# FM33FH0XX register map
File version: 1.0
CPU: SC000 r1p0, little endian, no MPU, no FPU, 3 interrupt priority bits
Registers are 32-bit, read-write, reset 0x0 unless marked. A register's access mark holds for its fields unless they carry their own. Offsets are from the block's base; [hi:lo] are bit positions; {n}, {i} and the like mark numbered series; 'fields as' and 'values as' point back to an identical list.

## DMA — DMA module information
Base 0x40000400
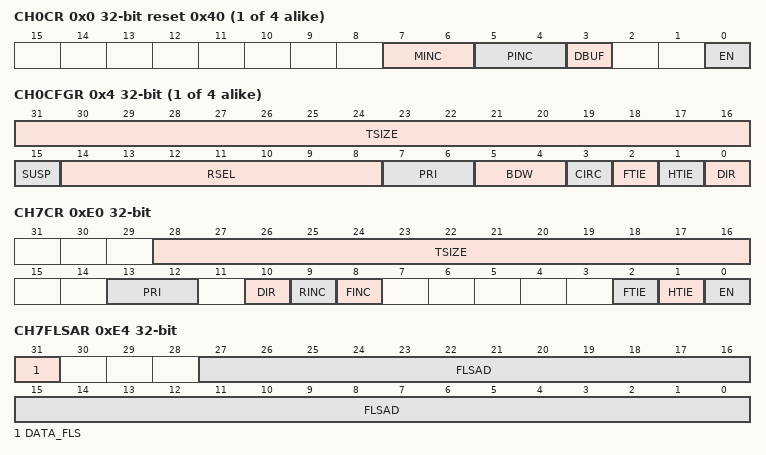
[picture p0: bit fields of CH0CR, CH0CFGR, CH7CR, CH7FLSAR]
{0x0+0x20*i} CH{i}CR reset 0x40 (i=0..3)
  [7:6] MINC — MINC field description
  [5:4] PINC — PINC field description
  [3] DBUF — DBUF field description
  [0] EN — EN field description
{0x4+0x20*i} CH{i}CFGR (i=0..3)
  [31:16] TSIZE — TSIZE field description
  [15] SUSP — SUSP field description
  [14:8] RSEL — RSEL field description
  [7:6] PRI — PRI field description
  [5:4] BDW — BDW field description
  [3] CIRC — CIRC field description
  [2] FTIE — FTIE field description
  [1] HTIE — HTIE field description
  [0] DIR — DIR field description
{0x8+0x20*i} CH{i}PAR (i=0..3)
  [31:0] PAD — PAD field description
{0xC+0x20*i} CH{i}MAR0 (i=0..3)
  [31:0] MAD0 — MAD0 field description
{0x10+0x20*i} CH{i}MAR1 (i=0..3)
  [31:0] MAD1 — MAD1 field description
0xE0 CH7CR
  [28:16] TSIZE — TSIZE field description
  [13:12] PRI — PRI field description
  [10] DIR — DIR field description
  [9] RINC — RINC field description
  [8] FINC — FINC field description
  [2] FTIE — FTIE field description
  [1] HTIE — HTIE field description
  [0] EN — EN field description
0xE4 CH7FLSAR
  [31] DATA_FLS — DATA_FLS field description
  [27:0] FLSAD — FLSAD field description
0xE8 CH7RAMAR
  [23:0] RAMAD — RAMAD field description
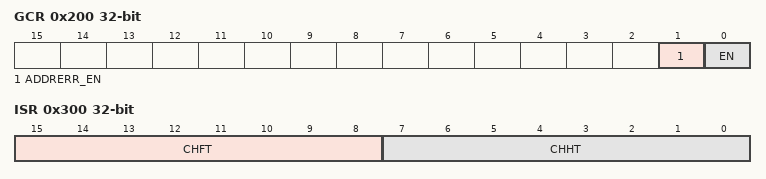
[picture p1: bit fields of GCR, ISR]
0x200 GCR
  [1] ADDRERR_EN — ADDRERR_EN field description
  [0] EN — EN field description
0x204 SWRR
  [6:0] SWTRIG — SWTRIG field description
0x300 ISR
  [15:8] CHFT — CHFT field description
  [7:0] CHHT — CHHT field description
{0x304+4i} CH{i}TFSADDR (i=0..3)
  [15:0] CNT ro — CNT field description

## FLS — FLS module information
Base 0x40001000
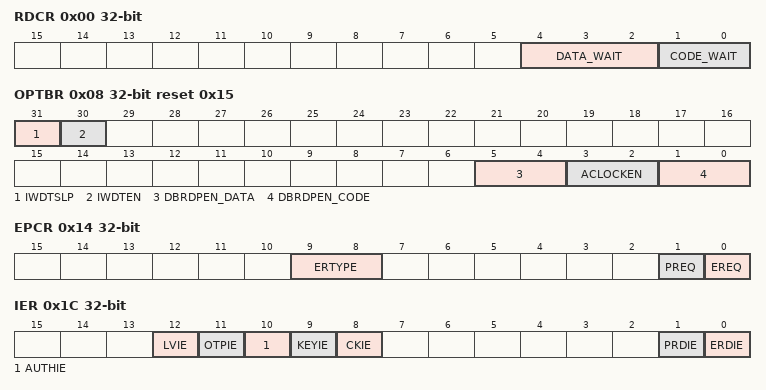
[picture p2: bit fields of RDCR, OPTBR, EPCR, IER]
0x00 RDCR
  [4:2] DATA_WAIT — DATA_WAIT field description
  [1:0] CODE_WAIT — CODE_WAIT field description
0x04 PFCR
  [0] EN — EN field description
0x08 OPTBR reset 0x15
  [31] IWDTSLP ro — IWDTSLP field description
  [30] IWDTEN ro — IWDTEN field description
  [5:4] DBRDPEN_DATA ro — DBRDPEN_DATA field description
  [3:2] ACLOCKEN ro — ACLOCKEN field description
  [1:0] DBRDPEN_CODE ro — DBRDPEN_CODE field description
0x14 EPCR
  [9:8] ERTYPE — ERTYPE field description
  [1] PREQ — PREQ field description
  [0] EREQ — EREQ field description
0x18 KEY
  [31:0] KEY wo — KEY field description
0x1C IER
  [12] LVIE — LVIE field description
  [11] OTPIE — OTPIE field description
  [10] AUTHIE — AUTHIE field description
  [9] KEYIE — KEYIE field description
  [8] CKIE — CKIE field description
  [1] PRDIE — PRDIE field description
  [0] ERDIE — ERDIE field description
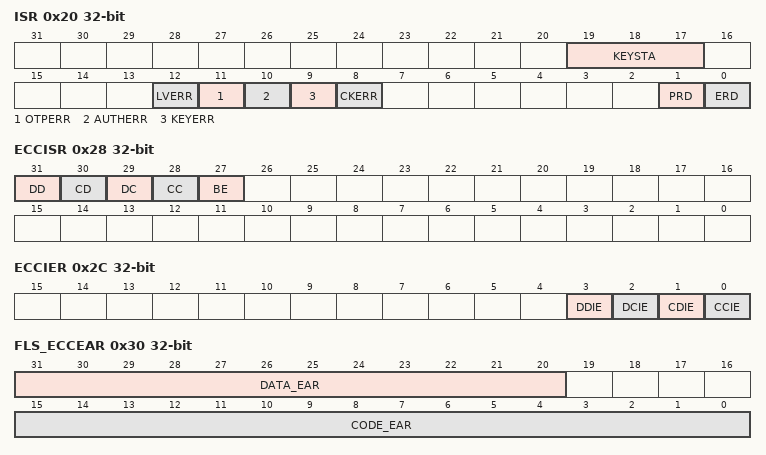
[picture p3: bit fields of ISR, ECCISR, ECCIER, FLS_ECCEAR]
0x20 ISR
  [19:17] KEYSTA ro — KEYSTA field description
  [12] LVERR — LVERR field description
  [11] OTPERR — OTPERR field description
  [10] AUTHERR — AUTHERR field description
  [9] KEYERR — KEYERR field description
  [8] CKERR — CKERR field description
  [1] PRD — PRD field description
  [0] ERD — ERD field description
0x28 ECCISR
  [31] DD — DD field description
  [30] CD — CD field description
  [29] DC — DC field description
  [28] CC — CC field description
  [27] BE — BE field description
0x2C ECCIER
  [3] DDIE — DDIE field description
  [2] DCIE — DCIE field description
  [1] CDIE — CDIE field description
  [0] CCIE — CCIE field description
0x30 FLS_ECCEAR
  [31:20] DATA_EAR ro — DATA_EAR field description
  [15:0] CODE_EAR ro — CODE_EAR field description
{0x5C+4i} ACLOCK{i} reset 0xFFFFFFFF (i=1..3)
  [31:0] LOCK{i} — LOCK{i} field description
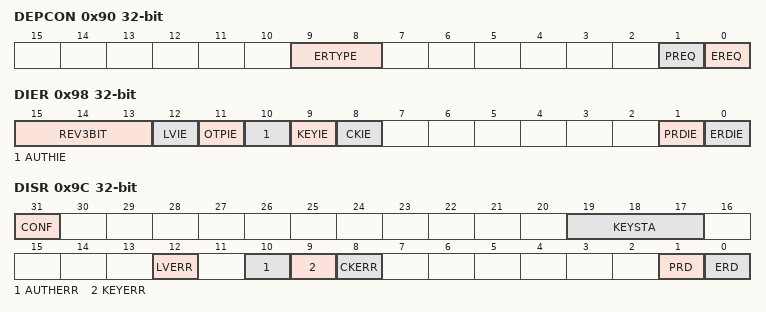
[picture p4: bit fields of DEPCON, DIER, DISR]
0x90 DEPCON
  fields as EPCR
0x94 DKEY
  [31:0] FLSKEY wo — FLSKEY field description
0x98 DIER
  [15:13] REV3BIT — REV3BIT field description
  [12] LVIE — LVIE field description
  [11] OTPIE — OTPIE field description
  [10] AUTHIE — AUTHIE field description
  [9] KEYIE — KEYIE field description
  [8] CKIE — CKIE field description
  [1] PRDIE — PRDIE field description
  [0] ERDIE — ERDIE field description
0x9C DISR
  [31] CONF ro — CONF field description
  [19:17] KEYSTA ro — KEYSTA field description
  [12] LVERR — LVERR field description
  [10] AUTHERR — AUTHERR field description
  [9] KEYERR — KEYERR field description
  [8] CKERR — CKERR field description
  [1] PRD — PRD field description
  [0] ERD — ERD field description
